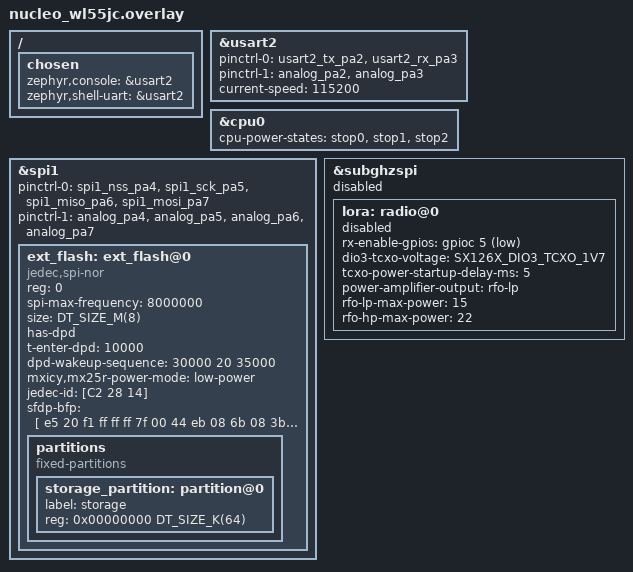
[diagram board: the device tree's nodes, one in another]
/delete-node/ &storage_partition;

/ {
	chosen {
		zephyr,console = &usart2;
		zephyr,shell-uart = &usart2;
	};
};

&usart2 {
	pinctrl-0 = <&usart2_tx_pa2 &usart2_rx_pa3>;
	pinctrl-1 = <&analog_pa2 &analog_pa3>;
	pinctrl-names = "default", "sleep";
	current-speed = <115200>;
	status = "okay";
};

&cpu0 {
	cpu-power-states = <&stop0 &stop1 &stop2>;
};


&spi1 {
	status = "okay";
	pinctrl-0 = <&spi1_nss_pa4 &spi1_sck_pa5
		     &spi1_miso_pa6 &spi1_mosi_pa7>;
	pinctrl-1 = <&analog_pa4 &analog_pa5
		     &analog_pa6 &analog_pa7>;
	pinctrl-names = "default", "sleep";

	ext_flash:ext_flash@0 {
		compatible = "jedec,spi-nor";
		reg = <0>;
		spi-max-frequency = <8000000>;
		size = <DT_SIZE_M(8)>;
		has-dpd;
		t-enter-dpd = <10000>;
		dpd-wakeup-sequence = <30000 20 35000>;
		mxicy,mx25r-power-mode = "low-power";
		
		jedec-id = [C2 28 14];
		sfdp-bfp = [
			e5 20 f1 ff  ff ff 7f 00  44 eb 08 6b  08 3b 04 bb
			ee ff ff ff  ff ff 00 ff  ff ff 00 ff  0c 20 0f 52
			10 d8 00 ff  23 72 f5 00  82 ed 04 b7  44 83 38 44
			30 b0 30 b0  f7 c4 d5 5c  00 be 29 ff  f0 d0 ff ff
		];
	};
};

&ext_flash {
	partitions {
		compatible = "fixed-partitions";
		#address-cells = <1>;
		#size-cells = <1>;

		storage_partition: partition@0 {
			label = "storage";
			reg = <0x00000000 DT_SIZE_K(64)>;
		};
	};
};

&subghzspi {
	status = "disabled";
	lora: radio@0 {
		status = "disabled";
		/* antenna-enable-gpios = <&gpioc 3 GPIO_ACTIVE_HIGH>; /* FE_CTRL3 */
		/* tx-enable-gpios = <&gpioc 4 GPIO_ACTIVE_LOW>; /* FE_CTRL1 */
		rx-enable-gpios = <&gpioc 5 GPIO_ACTIVE_LOW>; /* FE_CTRL2 */
		dio3-tcxo-voltage = <SX126X_DIO3_TCXO_1V7>;
		tcxo-power-startup-delay-ms = <5>;
		/* High-power output is selected as a consequence of using
		 * tx/rx-enable-gpio to control FE_CTRL1 and FE_CTRL2. Low-power
		 * output would require both FE_CTRL1 and FE_CTRL2 to be high,
		 * which is not currently supported by the driver.
		 */
		power-amplifier-output = "rfo-lp";
		rfo-lp-max-power = <15>;
		rfo-hp-max-power = <22>;
	};
};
